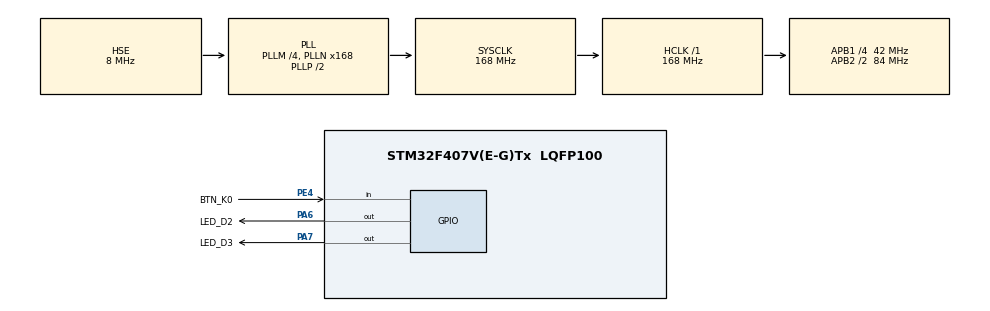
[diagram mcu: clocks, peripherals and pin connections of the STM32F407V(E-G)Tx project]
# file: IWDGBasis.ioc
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IWDG.Prescaler=IWDG_PRESCALER_32
IWDG.Reload=1000
Mcu.Family=STM32F4
Mcu.Name=STM32F407V(E-G)Tx
Mcu.Package=LQFP100
NVIC.PriorityGroup=NVIC_PRIORITYGROUP_4
PA13.Mode=Serial_Wire
PA13.Signal=SYS_JTMS-SWDIO
PA14.Mode=Serial_Wire
PA14.Signal=SYS_JTCK-SWCLK
PA6.GPIO_Label=LED_D2
PA6.PinState=GPIO_PIN_SET
PA6.Signal=GPIO_Output
PA7.GPIO_Label=LED_D3
PA7.PinState=GPIO_PIN_SET
PA7.Signal=GPIO_Output
PE4.GPIO_Label=BTN_K0
PE4.GPIO_PuPd=GPIO_PULLUP
PE4.Signal=GPIO_Input
PH0-OSC_IN.Mode=HSE-External-Oscillator
PH0-OSC_IN.Signal=RCC_OSC_IN
PH1-OSC_OUT.Mode=HSE-External-Oscillator
PH1-OSC_OUT.Signal=RCC_OSC_OUT
ProjectManager.HeapSize=0x200
ProjectManager.StackSize=0x400
ProjectManager.TargetToolchain=STM32CubeIDE
RCC.48MHZClocksFreq_Value=84000000
RCC.AHBFreq_Value=168000000
RCC.APB1CLKDivider=RCC_HCLK_DIV4
RCC.APB1Freq_Value=42000000
RCC.APB1TimFreq_Value=84000000
RCC.APB2CLKDivider=RCC_HCLK_DIV2
RCC.APB2Freq_Value=84000000
RCC.APB2TimFreq_Value=168000000
RCC.CortexFreq_Value=168000000
RCC.HCLKFreq_Value=168000000
RCC.HSE_VALUE=8000000
RCC.HSI_VALUE=16000000
RCC.LSE_VALUE=32768
RCC.PLLM=4
RCC.PLLN=168
RCC.PLLSourceVirtual=RCC_PLLSOURCE_HSE
RCC.SYSCLKFreq_VALUE=168000000
RCC.SYSCLKSource=RCC_SYSCLKSOURCE_PLLCLK
RCC.VCOOutputFreq_Value=336000000
VP_IWDG_VS_IWDG.Mode=IWDG_Activate
board=custom

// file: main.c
/* USER CODE BEGIN Header */
/**
  ******************************************************************************
  * @file           : main.c
  * @brief          : Main program body
  ******************************************************************************
  * @attention
  *
  * Copyright (c) 2024 STMicroelectronics.
  * All rights reserved.
  *
  * This software is licensed under terms that can be found in the LICENSE file
  * in the root directory of this software component.
  * If no LICENSE file comes with this software, it is provided AS-IS.
  *
  ******************************************************************************
  */
/* USER CODE END Header */
#include "main.h"

IWDG_HandleTypeDef hiwdg;

void SystemClock_Config(void);
static void MX_GPIO_Init(void);
static void MX_IWDG_Init(void);

int main(void)
{

  /* MCU Configuration--------------------------------------------------------*/

  /* Reset of all peripherals, Initializes the Flash interface and the Systick. */
  HAL_Init();

  /* Configure the system clock */
  SystemClock_Config();

  /* Initialize all configured peripherals */
  MX_GPIO_Init();
  MX_IWDG_Init();
  /* USER CODE BEGIN 2 */

  // 1 Check if the system has resumed from IWDG reset   ####################
  if (__HAL_RCC_GET_FLAG(RCC_FLAG_IWDGRST) != RESET)
  {
	  // IWDGRST flag set: turn LED2 ON
	  HAL_GPIO_WritePin(LED_D2_GPIO_Port, LED_D2_Pin, GPIO_PIN_RESET);

	  // Clear the reset flags
	  __HAL_RCC_CLEAR_RESET_FLAGS();

  }
  else
  {
	  // IWDGRST flag is not set: Turn LED2 OFF
  	  HAL_GPIO_WritePin(LED_D2_GPIO_Port, LED_D2_Pin, GPIO_PIN_SET);
  }
  /* USER CODE END 2 */

  /* Infinite loop */
  while (1)
  {

    /* USER CODE BEGIN 3 */

	  HAL_Delay(300);
	  //ON/OFF LED3 each 300 millisecond
  	  HAL_GPIO_TogglePin(LED_D3_GPIO_Port, LED_D3_Pin);

  	  // Refresh IWDG: reload counter
  	  if(HAL_IWDG_Refresh(&hiwdg) != HAL_OK)
  	  {
  		  //Refresh Error
  		  Error_Handler();

  	  }

  	  //Press Button k0 to generate a WDG event
  	  if(HAL_GPIO_ReadPin(BTN_K0_GPIO_Port, BTN_K0_Pin) == 0)
  	  {
  		  HAL_Delay(1000);
  	  }

  }
  /* USER CODE END 3 */
}

void SystemClock_Config(void)
{
  RCC_OscInitTypeDef RCC_OscInitStruct = {0};
  RCC_ClkInitTypeDef RCC_ClkInitStruct = {0};

  /** Configure the main internal regulator output voltage
  */
  __HAL_RCC_PWR_CLK_ENABLE();
  __HAL_PWR_VOLTAGESCALING_CONFIG(PWR_REGULATOR_VOLTAGE_SCALE1);

  /** Initializes the RCC Oscillators according to the specified parameters
  * in the RCC_OscInitTypeDef structure.
  */
  RCC_OscInitStruct.OscillatorType = RCC_OSCILLATORTYPE_LSI|RCC_OSCILLATORTYPE_HSE;
  RCC_OscInitStruct.HSEState = RCC_HSE_ON;
  RCC_OscInitStruct.LSIState = RCC_LSI_ON;
  RCC_OscInitStruct.PLL.PLLState = RCC_PLL_ON;
  RCC_OscInitStruct.PLL.PLLSource = RCC_PLLSOURCE_HSE;
  RCC_OscInitStruct.PLL.PLLM = 4;
  RCC_OscInitStruct.PLL.PLLN = 168;
  RCC_OscInitStruct.PLL.PLLP = RCC_PLLP_DIV2;
  RCC_OscInitStruct.PLL.PLLQ = 4;
  if (HAL_RCC_OscConfig(&RCC_OscInitStruct) != HAL_OK)
  {
    Error_Handler();
  }

  /** Initializes the CPU, AHB and APB buses clocks
  */
  RCC_ClkInitStruct.ClockType = RCC_CLOCKTYPE_HCLK|RCC_CLOCKTYPE_SYSCLK
                              |RCC_CLOCKTYPE_PCLK1|RCC_CLOCKTYPE_PCLK2;
  RCC_ClkInitStruct.SYSCLKSource = RCC_SYSCLKSOURCE_PLLCLK;
  RCC_ClkInitStruct.AHBCLKDivider = RCC_SYSCLK_DIV1;
  RCC_ClkInitStruct.APB1CLKDivider = RCC_HCLK_DIV4;
  RCC_ClkInitStruct.APB2CLKDivider = RCC_HCLK_DIV2;

  if (HAL_RCC_ClockConfig(&RCC_ClkInitStruct, FLASH_LATENCY_5) != HAL_OK)
  {
    Error_Handler();
  }
}

static void MX_IWDG_Init(void)
{

  hiwdg.Instance = IWDG;
  hiwdg.Init.Prescaler = IWDG_PRESCALER_32;
  hiwdg.Init.Reload = 1000;
  if (HAL_IWDG_Init(&hiwdg) != HAL_OK)
  {
    Error_Handler();
  }

}

static void MX_GPIO_Init(void)
{
  GPIO_InitTypeDef GPIO_InitStruct = {0};

  /* GPIO Ports Clock Enable */
  __HAL_RCC_GPIOE_CLK_ENABLE();
  __HAL_RCC_GPIOH_CLK_ENABLE();
  __HAL_RCC_GPIOA_CLK_ENABLE();

  /*Configure GPIO pin Output Level */
  HAL_GPIO_WritePin(GPIOA, LED_D2_Pin|LED_D3_Pin, GPIO_PIN_SET);

  /*Configure GPIO pin : BTN_K0_Pin */
  GPIO_InitStruct.Pin = BTN_K0_Pin;
  GPIO_InitStruct.Mode = GPIO_MODE_INPUT;
  GPIO_InitStruct.Pull = GPIO_PULLUP;
  HAL_GPIO_Init(BTN_K0_GPIO_Port, &GPIO_InitStruct);

  /*Configure GPIO pins : LED_D2_Pin LED_D3_Pin */
  GPIO_InitStruct.Pin = LED_D2_Pin|LED_D3_Pin;
  GPIO_InitStruct.Mode = GPIO_MODE_OUTPUT_PP;
  GPIO_InitStruct.Pull = GPIO_NOPULL;
  GPIO_InitStruct.Speed = GPIO_SPEED_FREQ_LOW;
  HAL_GPIO_Init(GPIOA, &GPIO_InitStruct);

}

void Error_Handler(void)
{
  __disable_irq();
  while (1)
  {
  }
}
